# MMCSD_0 register map
Vendor: Texas Instruments
Registers are 32-bit, access per field, reset 0x0 unless marked. A register's access mark holds for its fields unless they carry their own. Offsets are as the file gives them; [hi:lo] are bit positions.

## MMCSD_0 (part 2 of 2)
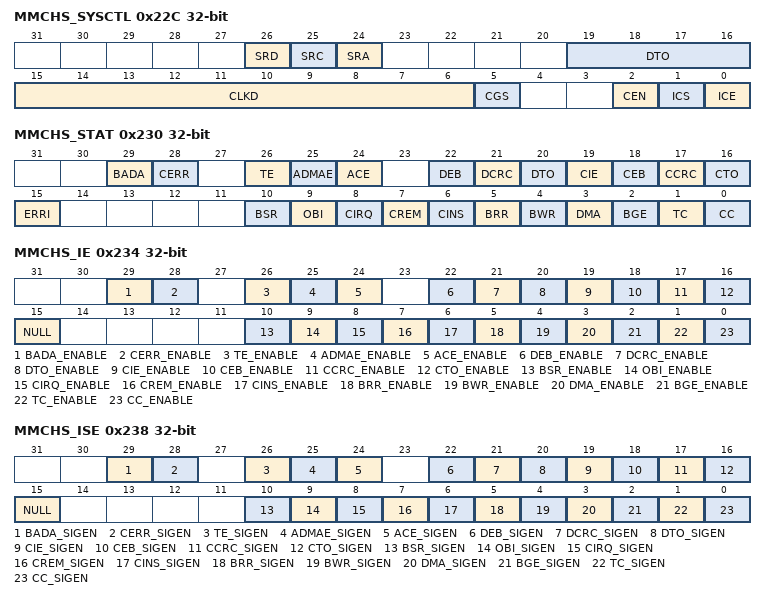
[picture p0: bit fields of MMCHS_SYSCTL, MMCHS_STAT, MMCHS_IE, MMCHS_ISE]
0x22C MMCHS_SYSCTL
  [26] SRD rw — Software reset for DAT line This bit is set to 1 for reset and released to 0 when completed. 0h (R/W) = Reset completed. 1h (R/W) = Software reset for DAT line.
  [25] SRC rw — Software reset for CMD line For more information about SRC bit manipulation, see 0h (R/W) = Reset completed. 1h (R/W) = Software reset for CMD line.
  [24] SRA rw — Software reset for all This bit is set to 1 for reset and released to 0 when completed. 0h (R/W) = Reset completed. 1h (R/W) = Software reset for all the design.
  [19:16] DTO rw — Data timeout counter value and busy timeout This value determines the interval by which DAT lines timeouts are detected. 0h (R/W) = TCF x 2^13. 1h (R/W) = TCF x 2^14. Eh (R/W) = TCF x 2^27. Fh (R/W) = Reserved.
  [15:6] CLKD rw — Clock frequency select These bits define the ratio between MMC_CLK_ADPI and the output clock frequency on the CLK pin of either the memory card (MMC, SD or SDIO). 0h (R/W) = MMC_CLK_ADPI bypass. 1h (R/W) = MMC_CLK_ADPI bypass. 2h (R/W) = MMC_CLK_ADPI / 2. 3h (R/W) = MMC_CLK_ADPI / 3. 3FFh (R/W) = MMC_CLK_ADPI / 1023.
  [5] CGS ro — Clock Generator Select - For SD cards Host Controller Version 3.00 supports this bit. This bit is used to select the clock generator mode in
  [2] CEN rw — Clock enable This bit controls if the clock is provided to the card or not. 0h (R/W) = The clock is not provided to the card. Clock frequency can be changed. 1h (R/W) = The clock is provided to the card and can be automatically gated when
  [1] ICS ro — Internal clock stable (status) This bit indicates either the internal clock is stable or not. 0h (R) = The internal clock is not stable. 1h (R) = The internal clock is stable after enabling the clock (
  [0] ICE rw — Internal clock enable This bit field controls the internal clock activity. 0h (R/W) = The internal clock is stopped (very low power state). 1h (R/W) = The internal clock oscillates and can be automatically gated when
0x230 MMCHS_STAT
  [29] BADA rw — Bad access to data space This bit is set automatically to indicate a bad access to buffer when not allowed: 0h (W) = Status bit unchanged. 1h (W) = Status is cleared. 0h (R) = No Interrupt. 1h (R) = Bad Access.
  [28] CERR rw — Card error This bit is set automatically when there is at least one error in a response of type R1, R1b, R6, R5 or R5b. Only bits referenced as type E(error) in status field in the response can set a card status error. An error bit in the response is flagged only if corresponding bit in card status response error 0h (W) = Status bit unchanged. 1h (W) = Status is cleared. 0h (R) = No Error. 1h (R) = Card error.
  [26] TE rw — Tuning Error This bit is set when an unrecoverable error is detected in a tuning circuit except during tuning procedure (Occurrence of an error during tuning procedure is indicated by Sampling Select). By detecting Tuning Error, Host Driver needs to abort a command executing and perform tuning. To reset tuning circuit, Sampling Clock shall be set to 0 before executing tuning procedure. The Tuning Error is higher priority than the other error interrupts generated during data transfer. By detecting Tuning Error, the Host Driver should discard data transferred by a current read/write command and retry data transfer after the Host Controller retrieved from tuning circuit error. The bit is set if the lock is lost (but not during the tuning process) or if the lock counter expires without the lock being asserted. If the latter happens, the SW can decide to ignore the interrupt and wait some more for the lock to be set. 0h (R/W) = No Error. 1h (R/W) = Error.
  [25] ADMAE rw — ADMA Error This bit is set when the Host Controller detects errors during ADMA based data transfer. The state of the ADMA at an error occurrence is saved in the ADMA Error Status Register. In addition, the Host Controller generates this interrupt when it detects invalid descriptor data (Valid=0) at the ST_FDS state. ADMA Error State in the ADMA Error Status indicates that an error occurs in ST_FDS state. The Host Driver may find that Valid bit is not set at the error descriptor. 0h (W) = Status bit unchanged. 1h (W) = Status is cleared. 0h (R) = No Interrupt. 1h (R) = ADMA error.
  [24] ACE rw — Auto CMD error Auto CMD12 and Auto CMD23 use this error status. This bit is set when detecting that one of the bits D00-D04 in Auto CMD Error Status register ( 0h (W) = Status bit unchanged. 1h (W) = Status is cleared. 0h (R) = No Error. 1h (R) = Auto CMD error.
  [22] DEB rw — Data End Bit error This bit is set automatically when detecting a 0 at the end bit position of read data on DAT line or at the end position of the CRC status in write mode. 0h (W) = Status bit unchanged. 1h (W) = Status is cleared. 0h (R) = No Error. 1h (R) = Data end bit error.
  [21] DCRC rw — Data CRC Error This bit is set automatically when there is a CRC16 error in the data phase response following a block read command or if there is a 3-bit CRC status different of a position '010' token during a block write command. 0h (W) = Status bit unchanged. 1h (W) = Status is cleared. 0h (R) = No Error. 1h (R) = Data CRC error.
  [20] DTO rw — Data timeout error This bit is set automatically according to the following conditions: 0h (W) = Status bit unchanged. 1h (W) = Status is cleared. 0h (R) = No error. 1h (R) = Time out.
  [19] CIE rw — Command index error This bit is set automatically when response index differs from corresponding command index previously emitted. It depends on the enable in 0h (W) = Status bit unchanged. 1h (W) = Status is cleared. 0h (R) = No error. 1h (R) = Command index error.
  [18] CEB rw — Command end bit error This bit is set automatically when detecting a 0 at the end bit position of a command response. 0h (W) = Status bit unchanged. 1h (W) = Status is cleared. 0h (R) = No error. 1h (R) = Command end bit error.
  [17] CCRC rw — Command CRC Error This bit is set automatically when there is a CRC7 error in the command response depending on the enable in 0h (W) = Status bit unchanged. 1h (W) = Status is cleared. 0h (R) = No Error. 1h (R) = Command CRC error.
  [16] CTO rw — Command Timeout Error This bit is set automatically when no response is received within 64 clock cycles from the end bit of the command. 0h (W) = Status bit unchanged. 1h (W) = Status is cleared. 0h (R) = No error. 1h (R) = Time Out.
  [15] ERRI ro — Error Interrupt If any of the bits in the Error Interrupt Status register ( 0h (R) = No Interrupt. 1h (R) = Error interrupt event(s) occurred.
  [10] BSR rw — Boot status received interrupt This bit is set automatically when 0h (W) = Status bit unchanged. 1h (W) = Status is cleared. 0h (R) = No Interrupt. 1h (R) = Boot status received interrupt.
  [9] OBI rw — Out-Of-Band interrupt This bit is set automatically when 0h (W) = Status bit unchanged. 1h (W) = Status is cleared. 0h (R) = No Out-Of-Band interrupt. 1h (R) = Interrupt Out-Of-Band occurs.
  [8] CIRQ ro — Card interrupt This bit is only used for SD and SDIO and CE-ATA cards. 0h (R) = No card interrupt. 1h (R) = Generate card interrupt.
  [7] CREM rw — Card removal This bit is set automatically when 0h (W) = Status bit unchanged. 1h (W) = Status is cleared. 0h (R) = Card state stable or Debouncing. 1h (R) = Card removed.
  [6] CINS rw — Card insertion This bit is set automatically when 0h (W) = Status bit unchanged. 1h (W) = Status is cleared. 0h (R) = Card state stable or debouncing. 1h (R) = Card inserted.
  [5] BRR rw — Buffer read ready This bit is set automatically during a read operation to the card (see class 2 - block oriented read commands) when one block specified by 0h (W) = Status bit unchanged. 1h (W) = Status is cleared. 0h (R) = Not Ready to read buffer. 1h (R) = Ready to read buffer.
  [4] BWR rw — Buffer write ready This bit is set automatically during a write operation to the card (see class 4 - block oriented write command) when the host can write a complete block as specified by 0h (W) = Status bit unchanged. 1h (W) = Status is cleared. 0h (R) = Not Ready to write buffer. 1h (R) = Ready to write buffer.
  [3] DMA rw — DMA interrupt This status is set when an interrupt is required in the ADMA instruction and after the data transfer completion. 0h (W) = Status bit unchanged. 1h (W) = Status is cleared. 0h (R) = Dma interrupt detected. 1h (R) = No dma interrupt.
  [2] BGE rw — Block gap event When a stop at block gap is requested ( 0h (W) = Status bit unchanged. 1h (W) = Status is cleared. 0h (R) = No block gap event. 1h (R) = Transaction stopped at block gap.
  [1] TC rw — Transfer completed This bit is always set when a read/write transfer is completed or between two blocks when the transfer is stopped due to a stop at block gap request ( 0h (W) = Status bit unchanged. 1h (W) = Status is cleared. 0h (R) = No transfer complete. 1h (R) = Data transfer complete.
  [0] CC rw — Command complete This bit is set when a 1-to-0 transition occurs in the register command inhibit ( 0h (W) = Status bit unchanged. 1h (W) = Status is cleared. 0h (R) = No Command complete. 1h (R) = Command complete.
0x234 MMCHS_IE
  [29] BADA_ENABLE rw — Bad access to data space Status Enable 0h (R/W) = Masked. 1h (R/W) = Enabled.
  [28] CERR_ENABLE rw — Card Error Status Enable 0h (R/W) = Masked. 1h (R/W) = Enabled.
  [26] TE_ENABLE rw — Tuning Error Status Enable 0h (R/W) = Masked. 1h (R/W) = Enabled.
  [25] ADMAE_ENABLE rw — ADMA Error Status Enable 0h (R/W) = Masked. 1h (R/W) = Enabled.
  [24] ACE_ENABLE rw — Auto CMD Error Status Enable 0h (R/W) = Masked. 1h (R/W) = Enabled.
  [22] DEB_ENABLE rw — Data End Bit Error Status Enable 0h (R/W) = Masked. 1h (R/W) = Enabled.
  [21] DCRC_ENABLE rw — Data CRC Error Status Enable 0h (R/W) = Masked. 1h (R/W) = Enabled.
  [20] DTO_ENABLE rw — Data Timeout Error Status Enable 0h (R/W) = The data timeout detection is deactivated. The host controller provides the clock to the card until the card sends the data or the transfer is aborted. 1h (R/W) = The data timeout detection is enabled.
  [19] CIE_ENABLE rw — Command Index Error Status Enable 0h (R/W) = Masked. 1h (R/W) = Enabled.
  [18] CEB_ENABLE rw — Command End Bit Error Status Enable 0h (R/W) = Masked. 1h (R/W) = Enabled.
  [17] CCRC_ENABLE rw — Command CRC Error Status Enable 0h (R/W) = Masked. 1h (R/W) = Enabled.
  [16] CTO_ENABLE rw — Command Timeout Error Status Enable 0h (R/W) = Masked. 1h (R/W) = Enabled.
  [15] NULL ro — Fixed to 0 The host driver shall control error interrupts using the Error Interrupt Signal Enable register.
  [10] BSR_ENABLE rw — Boot Status Enable A write to this bit field when 0h (R/W) = Masked. 1h (R/W) = Enabled.
  [9] OBI_ENABLE rw — Out-of-Band Status Enable A write to this bit field when 0h (R/W) = Masked. 1h (R/W) = Enabled.
  [8] CIRQ_ENABLE rw — Card Status Enable A clear of this bit also clears the corresponding status bit. 0h (R/W) = Masked. 1h (R/W) = Enabled.
  [7] CREM_ENABLE rw — Card Removal Status Enable 0h (R/W) = Masked. 1h (R/W) = Enabled.
  [6] CINS_ENABLE rw — Card Insertion Status Enable 0h (R/W) = Masked. 1h (R/W) = Enabled.
  [5] BRR_ENABLE rw — Buffer Read Ready Status Enable 0h (R/W) = Masked. 1h (R/W) = Enabled.
  [4] BWR_ENABLE rw — Buffer Write Ready Status Enable 0h (R/W) = Masked. 1h (R/W) = Enabled.
  [3] DMA_ENABLE rw — DMA Status Enable 0h (R/W) = Masked. 1h (R/W) = Enabled.
  [2] BGE_ENABLE rw — Block Gap Event Status Enable 0h (R/W) = Masked. 1h (R/W) = Enabled.
  [1] TC_ENABLE rw — Transfer Complete Status Enable 0h (R/W) = Masked. 1h (R/W) = Enabled.
  [0] CC_ENABLE rw — Command Complete Status Enable 0h (R/W) = Masked. 1h (R/W) = Enabled.
0x238 MMCHS_ISE
  [29] BADA_SIGEN rw — Bad access to data space Signal Enable 0h (R/W) = Masked. 1h (R/W) = Enabled.
  [28] CERR_SIGEN rw — Card Error Interrupt Signal Enable 0h (R/W) = Masked. 1h (R/W) = Enabled.
  [26] TE_SIGEN rw — Tuning Error Signal Enable 0h (R/W) = Masked. 1h (R/W) = Enabled.
  [25] ADMAE_SIGEN rw — ADMA Error Signal Enable 0h (R/W) = Masked. 1h (R/W) = Enabled.
  [24] ACE_SIGEN rw — Auto CMD Error Signal Enable 0h (R/W) = Masked. 1h (R/W) = Enabled.
  [22] DEB_SIGEN rw — Data End Bit Error Signal Enable 0h (R/W) = Masked. 1h (R/W) = Enabled.
  [21] DCRC_SIGEN rw — Data CRC Error Signal Enable 0h (R/W) = Masked. 1h (R/W) = Enabled.
  [20] DTO_SIGEN rw — Data Timeout Error Signal Enable 0h (R/W) = Masked. 1h (R/W) = Enabled.
  [19] CIE_SIGEN rw — Command Index Error Signal Enable 0h (R/W) = Masked. 1h (R/W) = Enabled.
  [18] CEB_SIGEN rw — Command End Bit Error Signal Enable 0h (R/W) = Masked. 1h (R/W) = Enabled.
  [17] CCRC_SIGEN rw — Command CRC Error Signal Enable 0h (R/W) = Masked. 1h (R/W) = Enabled.
  [16] CTO_SIGEN rw — Command timeout Error Signal Enable 0h (R/W) = Masked. 1h (R/W) = Enabled.
  [15] NULL ro — Fixed to 0 The host driver shall control error interrupts using the Error Interrupt Signal Enable register.
  [10] BSR_SIGEN rw — Boot Status Signal Enable A write to this bit field when 0h (R/W) = Masked. 1h (R/W) = Enabled.
  [9] OBI_SIGEN rw — Out-Of-Band Interrupt Signal Enable A write to this bit field when 0h (R/W) = Masked. 1h (R/W) = Enabled.
  [8] CIRQ_SIGEN rw — Card Interrupt Signal Enable 0h (R/W) = Masked. 1h (R/W) = Enabled.
  [7] CREM_SIGEN rw — Card Removal Signal Enable 0h (R/W) = Masked. 1h (R/W) = Enabled.
  [6] CINS_SIGEN rw — Card Insertion Signal Enable 0h (R/W) = Masked. 1h (R/W) = Enabled.
  [5] BRR_SIGEN rw — Buffer Read Ready Signal Enable 0h (R/W) = Masked. 1h (R/W) = Enabled.
  [4] BWR_SIGEN rw — Buffer Write Ready Signal Enable 0h (R/W) = Masked. 1h (R/W) = Enabled.
  [3] DMA_SIGEN rw — DMA Interrupt Signal Enable 0h (R/W) = Masked. 1h (R/W) = Enabled.
  [2] BGE_SIGEN rw — Black Gap Event Signal Enable 0h (R/W) = Masked. 1h (R/W) = Enabled.
  [1] TC_SIGEN rw — Transfer Completed Status Enable 0h (R/W) = Masked. 1h (R/W) = Enabled.
  [0] CC_SIGEN rw — Command Complete Status Enable 0h (R/W) = Masked. 1h (R/W) = Enabled.
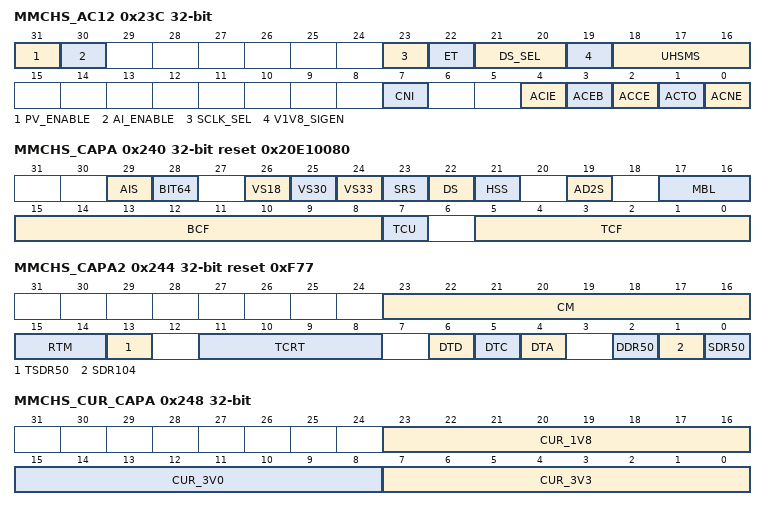
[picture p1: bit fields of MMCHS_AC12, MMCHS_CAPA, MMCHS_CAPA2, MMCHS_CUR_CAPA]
0x23C MMCHS_AC12
  [31] PV_ENABLE rw — Preset Value Enable Host Controller Version 3.00 supports this bit. 0h (R/W) = SDCLK and Driver Strength (DS_SEL) are controlled by Host Driver. 1h (R/W) = Automatic Selection by Preset Value are Enabled.
  [30] AI_ENABLE rw — Asynchronous Interrupt Enable This bit can be set to 1 if a card supports asynchronous interrupts and 0h (R/W) = Disabled. 1h (R/W) = Enabled.
  [23] SCLK_SEL rw — Sampling Clock Select Host Controller uses this bit to select sampling clock to receive CMD and DAT. This bit is set by tuning procedure and valid after the completion of tuning (when 0h (R/W) = Fixed clock is used to sample data. 1h (R/W) = Tuned clock is used to sample data.
  [22] ET rw — Execute Tuning This bit is set to 1 to start tuning procedure and automatically cleared when tuning procedure is completed. The result of tuning is indicated to 0h (R/W) = Not Tuned or Tuning Completed. 1h (R/W) = Execute Tuning.
  [21:20] DS_SEL rw — Driver Strength Select Host Controller output driver in 1.8 V signaling is selected by this bit. In 3.3 V signaling, this field is not effective. This field can be set depending on Driver Type A, C and D support bits (DTA, DTC and DTD respectively) in the 0h (R/W) = Driver Type B is selected (Default). 1h (R/W) = Driver Type A is selected. 2h (R/W) = Driver Type C is selected. 3h (R/W) = Driver Type D is selected.
  [19] V1V8_SIGEN rw — 1.8 V Signaling Enable This bit controls voltage regulator for I/O cell. 3.3 V is supplied to the card regardless of signaling voltage. 0h (R/W) = 3.3 V Signaling. 1h (R/W) = 1.8 V Signaling.
  [18:16] UHSMS rw — UHS Mode Select This field is used to select one of UHS-I modes and effective when 1.8 V Signaling Enable is set to 1. 0h (R/W) = SDR12. 1h (R/W) = SDR25. 2h (R/W) = SDR50. 3h (R/W) = SDR104. 4h (R/W) = DDR50. 5h (R/W) = Reserved. 6h (R/W) = Reserved. 7h (R/W) = Reserved.
  [7] CNI ro — Command Not Issued By Auto CMD12 Error Setting this bit to 1 means CMD_wo_DAT is not executed due to an Auto CMD12 Error (D04-D01) in this bit field. 0h (R) = No error. 1h (R) = Command not issued.
  [4] ACIE ro — Auto CMD Index Error - For Auto CMD12 and Auto CMD23 This bit is set if the Command Index error occurs in response to a command. 0h (R) = No error. 1h (R) = Error.
  [3] ACEB ro — Auto CMD End Bit Error - For Auto CMD12 and Auto CMD23 This bit is set when detecting that the end bit of command response is 0. 0h (R) = No error. 1h (R) = End bit Error Generated.
  [2] ACCE ro — Auto CMD CRC Error - For Auto CMD12 and Auto CMD23 This bit is set when detecting a CRC error in the command response. 0h (R) = No error. 1h (R) = CRC Error Generated.
  [1] ACTO ro — Auto CMD Timeout Error - For Auto CMD12 and Auto CMD23 This bit is set if no response is returned within 64 SDCLK cycles from the end bit of command. 0h (R) = No error. 1h (R) = Auto CMD Time Out.
  [0] ACNE ro — Auto CMD12 Not Executed If memory multiple block data transfer is not started due to command error, this bit is not set because it is not necessary to issue Auto CMD12. Setting this bit to 1 means the Host Controller cannot issue Auto CMD12 to stop memory multiple block data transfer due to some error. If this bit is set to 1, other error status bits (D04-D01) are meaningless. 0h (R) = Auto CMD12 Executed. 1h (R) = Auto CMD12 Not Executed.
0x240 MMCHS_CAPA reset 0x20E10080
  [29] AIS ro — Asynchronous Interrupt Support Refer to SDIO Specification Version 3.00 about asynchronous interrupt. 0h (R) = Asynchronous Interrupt Not Supported. 1h (R) = Asynchronous Interrupt Supported.
  [28] BIT64 ro — 64 Bit System Bus Support Setting 1 to this bit indicates that the Host Controller supports 64-bit address descriptor mode and is connected to 64-bit address system bus. 0h (R) = 32 bit System bus address. 1h (R) = 64 bit System bus address.
  [26] VS18 rw — Voltage support 1.8 V Initialization of this bit field (via a write access to this bit field) depends on the system capabilities. The host driver shall not modify this bit field after the initilaization. 0h (W) = 1.8 V Not supported. 1h (W) = 1.8 V Supported. 0h (R) = 1.8 V Not Supported. 1h (R) = 1.8 V Supported.
  [25] VS30 rw — Voltage support 3.0 V Initialization of this bit field (via a write access to this bit field) depends on the system capabilities. The host driver shall not modify this bit field after the initilaization. 0h (W) = 3.0 V Not supported. 1h (W) = 3.0 V Supported. 0h (R) = 3.0 V Not Supported. 1h (R) = 3.0 V Supported.
  [24] VS33 rw — Voltage support 3.3 V Initialization of this bit field (via a write access to this bit field) depends on the system capabilities. The host driver shall not modify this bit field after the initilaization. 0h (W) = 3.3 V Not supported. 1h (W) = 3.3 V Supported. 0h (R) = 3.3 V Not Supported. 1h (R) = 3.3 V Supported.
  [23] SRS ro — Suspend/Resume support (SDIO cards only) This bit indicates whether the host controller supports Suspend/Resume functionality. 0h (R) = The Host controller does not Suspend/Resume functionality. 1h (R) = The Host controller supports Suspend/Resume functionality.
  [22] DS ro — DMA support This bit indicates that the Host Controller is able to use DMA to transfer data between system memory and the Host Controller directly. 0h (R) = DMA Not Supported. 1h (R) = DMA Supported.
  [21] HSS ro — High speed support This bit indicates that the host controller supports high speed operations and can supply an up-to maximum card frequency. 0h (R) = High Speed Not Supported. 1h (R) = High Speed Supported.
  [19] AD2S ro — ADMA2 Support This bit indicates whether the Host Controller is capable of using ADMA2. It depends on setting of generic parameter MADMA_EN. 0h (R) = ADMA2 not Supported. 1h (R) = ADMA2 Supported.
  [17:16] MBL ro — Maximum block length This value indicates the maximum block size that the host driver can read and write to the buffer in the host controller. 0h (R) = 512 bytes. 1h (R) = 1024 bytes. 2h (R) = 2048 bytes.
  [15:8] BCF ro — Base Clock Frequency For SD Clock This value indicates the base (maximum) clock frequency for the SD Clock. 0h (R) = The value indicating the base (maximum) frequency for the output clock provided to the card is system dependent and is not available in this bit filed. Get the information via another method.
  [7] TCU ro — Timeout clock unit This bit shows the unit of base clock frequency used to detect Data Timeout Error ( 0h (R) = KHz. 1h (R) = MHz.
  [5:0] TCF ro — Timeout clock frequency The timeout clock frequency is used to detect Data Timeout Error ( 0h (R) = The timeout clock frequency depends on the frequency of the clock provided to the card. The value of the timeout clock frequency is not available in this bit field.
0x244 MMCHS_CAPA2 ro reset 0xF77
  [23:16] CM — Clock Multiplier This field indicates clock multiplier value of programmable clock generator. Refer to
  [15:14] RTM — Re-Tuning Modes This field selects re-tuning method and limits the maximum data length. 0h (R) = Timer - Max data length 4 MB. 1h (R) = Timer and Re-Tuning Request - Max data length 4 MB. 2h (R) = Auto Re-Tuning (for transfer) - Timer and Re-Tuning Request. 3h (R) = Reserved.
  [13] TSDR50 — Use Tuning for SDR50 If this bit is set to 1, this Host Controller requires tuning to operate SDR50. 0h (R) = SDR50 does not require tuning. 1h (R) = SDR50 requires tuning.
  [11:8] TCRT — Timer Count for Re-Tuning This field indicates an initial value of the Re-Tuning Timer for Re-Tuning Mode 1 to 3. Setting to 0 disables Re-Tuning Timer. 0h (R) = Re-Tuning Timer disabled. 1h (R) = 1 second. 2h (R) = 2 seconds. 3h (R) = 4 seconds. 4h (R) = 8 seconds. 5h (R) = 16 seconds. 6h (R) = 32 seconds. 7h (R) = 64 seconds. 8h (R) = 128 seconds. 9h (R) = 256 seconds. Ah (R) = 512 seconds. Bh (R) = 1024 seconds. Ch (R) = Reserved. Dh (R) = Reserved. Eh (R) = Reserved. Fh (R) = Get information from other source.
  [6] DTD — Driver Type D Support This bit indicates support of Driver Type D for 1.8 Signaling. 0h (R) = Driver Type D is Not Supported. 1h (R) = Driver Type D is Supported.
  [5] DTC — Driver Type C Support This bit indicates support of Driver Type C for 1.8 Signaling. 0h (R) = Driver Type C is Not Supported. 1h (R) = Driver Type C is Supported.
  [4] DTA — Driver Type A Support This bit indicates support of Driver Type A for 1.8 Signaling. 0h (R) = Driver Type A is Not Supported. 1h (R) = Driver Type A is Supported.
  [2] DDR50 — DDR50 Support 0h (R) = DDR50 is Not Supported. 1h (R) = DDR50 is Supported.
  [1] SDR104 — SDR104 Support SDR104 requires tuning. 0h (R) = SDR104 is Not Supported. 1h (R) = SDR104 is Supported.
  [0] SDR50 — SDR50 Support If SDR104 is supported, this bit shall be set to 1. Bit 13 indicates whether SDR50 requires tuning or not. 0h (R) = SDR50 is Not Supported. 1h (R) = SDR50 is Supported.
0x248 MMCHS_CUR_CAPA
  [23:16] CUR_1V8 rw — Maximum current for 1.8 V 0h (R) = The maximum current capability for this voltage is not available. Feature not implemented.
  [15:8] CUR_3V0 rw — Maximum current for 3.0 V 0h (R) = The maximum current capability for this voltage is not available. Feature not implemented.
  [7:0] CUR_3V3 rw — Maximum current for 3.3 V 0h (R) = The maximum current capability for this voltage is not available. Feature not implemented.
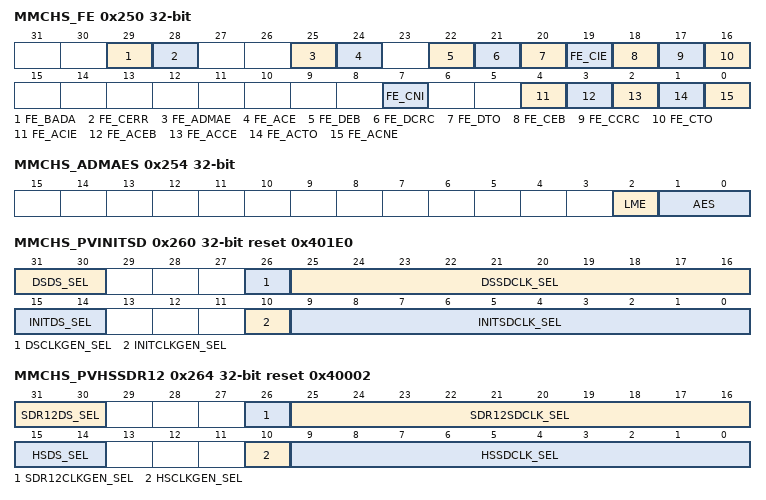
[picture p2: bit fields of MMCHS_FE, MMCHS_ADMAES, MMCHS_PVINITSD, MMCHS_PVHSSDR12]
0x250 MMCHS_FE
  [29] FE_BADA wo — Force Event Bad access to data space 0h (W) = No effect, No Interrupt. 1h (W) = Interrupt Forced.
  [28] FE_CERR wo — Force Event Card error 0h (W) = No effect, No Interrupt. 1h (W) = Interrupt Forced.
  [25] FE_ADMAE wo — Force Event ADMA Error 0h (W) = No effect, No Interrupt. 1h (W) = Interrupt Forced.
  [24] FE_ACE wo — Force Event for Auto CMD Error - For Auto CMD12 and Auto CMD23 0h (W) = No effect, No Interrupt. 1h (W) = Interrupt Forced.
  [22] FE_DEB wo — Force Event Data End Bit error 0h (W) = No effect, No Interrupt. 1h (W) = Interrupt Forced.
  [21] FE_DCRC wo — Force Event Data CRC Error 0h (W) = No effect, No Interrupt. 1h (W) = Interrupt Forced.
  [20] FE_DTO wo — Force Event Data Timeout Error 0h (W) = No effect, No Interrupt. 1h (W) = Interrupt Forced.
  [19] FE_CIE wo — Force Event Command Index Error 0h (W) = No effect, No Interrupt. 1h (W) = Interrupt Forced.
  [18] FE_CEB wo — Force Event Command End Bit Error 0h (W) = No effect, No Interrupt. 1h (W) = Interrupt Forced.
  [17] FE_CCRC wo — Force Event Command CRC Error 0h (W) = No effect, No Interrupt. 1h (W) = Interrupt Forced.
  [16] FE_CTO wo — Command Timeout Error This bit is set automatically when no response is received within 64 clock cycles from the end bit of the command. 0h (W) = Status bit unchanged. 1h (W) = Status is cleared.
  [7] FE_CNI wo — Force Event Command not issue by Auto CMD12 error 0h (W) = No effect, No Interrupt. 1h (W) = Interrupt Forced.
  [4] FE_ACIE wo — Force Event for Auto CMD Index Error - For Auto CMD12 and Auto CMD23 0h (W) = No effect, No Interrupt. 1h (W) = Interrupt Forced.
  [3] FE_ACEB wo — Force Event Auto CMD End Bit Error 0h (W) = No effect, No Interrupt. 1h (W) = Interrupt Forced.
  [2] FE_ACCE wo — Force Event Auto CMD CRC Error 0h (W) = No effect, No Interrupt. 1h (W) = Interrupt Forced.
  [1] FE_ACTO wo — Force Event Auto CMD Timeout Error 0h (W) = No effect, No Interrupt. 1h (W) = Interrupt Forced.
  [0] FE_ACNE wo — Force Event Auto CMD12 Not Executed 0h (W) = No effect, No Interrupt. 1h (W) = Interrupt Forced.
0x254 MMCHS_ADMAES
  [2] LME rw — ADMA Length Mismatch Error 0h (R/W) = No Error. 1h (R/W) = Error.
  [1:0] AES rw — ADMA Error State his field indicates the state of ADMA when error is occurred during ADMA data transfer. 0h (R/W) = ST_STOP (Stop DMA) Contents of SYS_SDR register. 1h (R/W) = ST_STOP (Stop DMA) Points the error descriptor. 2h (R/W) = Never set this state (Not used). 3h (R/W) = ST_TFR (Transfer Data) Points the next of the error descriptor.
0x258 MMCHS_ADMASAL rw
  [31:0] ADMA_A32B — ADMA System address 32 bits
0x260 MMCHS_PVINITSD ro reset 0x401E0
  [31:30] DSDS_SEL — Driver Strength Select Value - Default Speed mode Driver Strength is supported by 1.8 V signaling bus speed modes. This field is meaningless for 3.3 V signaling. 0h (R) = Driver Type B is Selected. 1h (R) = Driver Type A is Selected. 2h (R) = Driver Type C is Selected. 3h (R) = Driver Type D is Selected.
  [26] DSCLKGEN_SEL — Clock Generator Select Value - Default Speed mode This bit is effective when Host Controller supports programmable clock generator. 0h (R) = Host Controller Ver2.00 Compatible Clock Generator. 1h (R) = Programmable Clock Generator.
  [25:16] DSSDCLK_SEL — SDCLK Frequency Select Value - Default Speed mode 10-bit preset value to set
  [15:14] INITDS_SEL — Driver Strength Select Value - Initialization mode Driver Strength is supported by 1.8 V signaling bus speed modes. This field is meaningless for 3.3 V signaling. 0h (R) = Driver Type B is Selected. 1h (R) = Driver Type A is Selected. 2h (R) = Driver Type C is Selected. 3h (R) = Driver Type D is Selected.
  [10] INITCLKGEN_SEL — Clock Generator Select Value - Initialization mode This bit is effective when Host Controller supports programmable clock generator. 0h (R) = Host Controller Ver2.00 Compatible Clock Generator. 1h (R) = Programmable Clock Generator.
  [9:0] INITSDCLK_SEL — SDCLK Frequency Select Value - Initialization mode 10-bit preset value to set
0x264 MMCHS_PVHSSDR12 ro reset 0x40002
  [31:30] SDR12DS_SEL — Driver Strength Select Value - SDR12 mode Driver Strength is supported by 1.8 V signaling bus speed modes. This field is meaningless for 3.3 V signaling. 0h (R) = Driver Type B is Selected. 1h (R) = Driver Type A is Selected. 2h (R) = Driver Type C is Selected. 3h (R) = Driver Type D is Selected.
  [26] SDR12CLKGEN_SEL — Clock Generator Select Value - SDR12 mode This bit is effective when Host Controller supports programmable clock generator. 0h (R) = Host Controller Ver2.00 Compatible Clock Generator. 1h (R) = Programmable Clock Generator.
  [25:16] SDR12SDCLK_SEL — SDCLK Frequency Select Value - SDR12 mode 10-bit preset value to set
  [15:14] HSDS_SEL — Driver Strength Select Value - High Speed mode Driver Strength is supported by 1.8 V signaling bus speed modes. This field is meaningless for 3.3 V signaling. 0h (R) = Driver Type B is Selected. 1h (R) = Driver Type A is Selected. 2h (R) = Driver Type C is Selected. 3h (R) = Driver Type D is Selected.
  [10] HSCLKGEN_SEL — Clock Generator Select Value - High Speed mode This bit is effective when Host Controller supports programmable clock generator. 0h (R) = Host Controller Ver2.00 Compatible Clock Generator. 1h (R) = Programmable Clock Generator.
  [9:0] HSSDCLK_SEL — SDCLK Frequency Select Value - High Speed mode 10-bit preset value to set
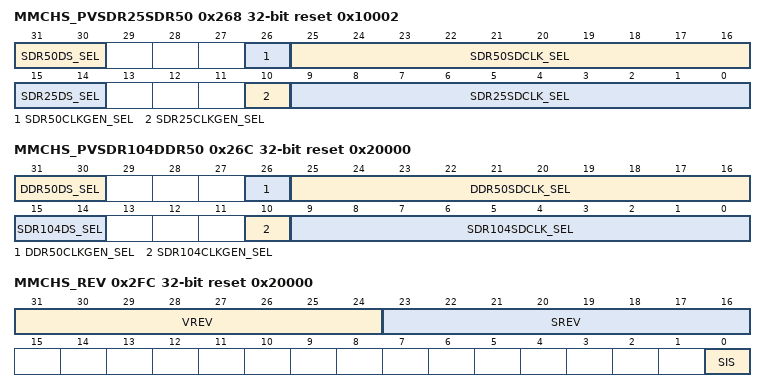
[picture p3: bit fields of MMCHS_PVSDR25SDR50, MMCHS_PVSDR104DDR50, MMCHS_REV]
0x268 MMCHS_PVSDR25SDR50 ro reset 0x10002
  [31:30] SDR50DS_SEL — Driver Strength Select Value - SDR50 mode Driver Strength is supported by 1.8 V signaling bus speed modes. This field is meaningless for 3.3 V signaling. 0h (R) = Driver Type B is Selected. 1h (R) = Driver Type A is Selected. 2h (R) = Driver Type C is Selected. 3h (R) = Driver Type D is Selected.
  [26] SDR50CLKGEN_SEL — Clock Generator Select Value - SDR50 mode This bit is effective when Host Controller supports programmable clock generator. 0h (R) = Host Controller Ver2.00 Compatible Clock Generator. 1h (R) = Programmable Clock Generator.
  [25:16] SDR50SDCLK_SEL — SDCLK Frequency Select Value - SDR50 mode 10-bit preset value to set
  [15:14] SDR25DS_SEL — Driver Strength Select Value - SDR25 mode Driver Strength is supported by 1.8 V signaling bus speed modes. This field is meaningless for 3.3 V signaling. 0h (R) = Driver Type B is Selected. 1h (R) = Driver Type A is Selected. 2h (R) = Driver Type C is Selected. 3h (R) = Driver Type D is Selected.
  [10] SDR25CLKGEN_SEL — Clock Generator Select Value - SDR25 mode This bit is effective when Host Controller supports programmable clock generator. 0h (R) = Host Controller Ver2.00 Compatible Clock Generator. 1h (R) = Programmable Clock Generato.
  [9:0] SDR25SDCLK_SEL — SDCLK Frequency Select Value - SDR25 mode 10-bit preset value to set
0x26C MMCHS_PVSDR104DDR50 ro reset 0x20000
  [31:30] DDR50DS_SEL — Driver Strength Select Value - DDR50 mode Driver Strength is supported by 1.8 V signaling bus speed modes. This field is meaningless for 3.3 V signaling. 0h (R) = Driver Type B is Selected. 1h (R) = Driver Type A is Selected. 2h (R) = Driver Type C is Selected. 3h (R) = Driver Type D is Selected.
  [26] DDR50CLKGEN_SEL — Clock Generator Select Value - DDR50 mode This bit is effective when Host Controller supports programmable clock generator. 0h (R) = Host Controller Ver2.00 Compatible Clock Generator. 1h (R) = Programmable Clock Generator.
  [25:16] DDR50SDCLK_SEL — SDCLK Frequency Select Value - DDR50 mode 10-bit preset value to set
  [15:14] SDR104DS_SEL — Driver Strength Select Value - SDR104 mode Driver Strength is supported by 1.8 V signaling bus speed modes. This field is meaningless for 3.3 V signaling. 0h (R) = Driver Type B is Selected. 1h (R) = Driver Type A is Selected. 2h (R) = Driver Type C is Selected. 3h (R) = Driver Type D is Selected.
  [10] SDR104CLKGEN_SEL — Clock Generator Select Value - SDR104 mode This bit is effective when Host Controller supports programmable clock generator. 0h (R) = Host Controller Ver2.00 Compatible Clock Generator. 1h (R) = Programmable Clock Generator.
  [9:0] SDR104SDCLK_SEL — SDCLK Frequency Select Value - SDR104 mode 10-bit preset value to set
0x2FC MMCHS_REV ro reset 0x20000 (reset mask 0xFFFFFF)
  [31:24] VREV — Vendor Version Number: MMC revision [7-4] Major revision
  [23:16] SREV — Specification Version Number This status indicates the Host Controller Spec. Version. The upper and lower 4-bits indicate the version. 0h (R) = SD Host Specification Version 1.00. 1h (R) = SD Host Specification Version 2.00 - Including the feature of the ADMA and Test Register. 2h (R) = SD Host Specification Version 3.00. 3h (R) = Reserved.
  [0] SIS — Slot Interrupt Status This status bit indicates the inverted state of interrupt signal for the module.
